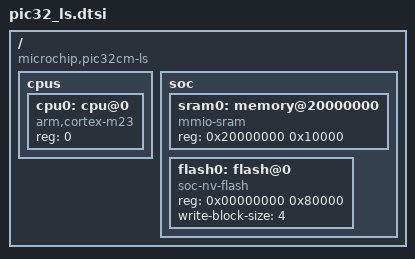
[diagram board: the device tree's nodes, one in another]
/*
 * Copyright (c) 2026
 *
 * SPDX-License-Identifier: Apache-2.0
 */

/* Common definitions for PIC32CM LS devices */

#include <arm/armv8-m.dtsi>

/ {
	compatible = "microchip,pic32cm-ls";

	cpus {
		#address-cells = <1>;
		#size-cells = <0>;

		cpu0: cpu@0 {
			device_type = "cpu";
			compatible = "arm,cortex-m23";
			reg = <0>;
		};
	};

	soc {
		#address-cells = <1>;
		#size-cells = <1>;

		sram0: memory@20000000 {
			compatible = "mmio-sram";
			reg = <0x20000000 0x10000>;
		};

		flash0: flash@0 {
			compatible = "soc-nv-flash";
			reg = <0x00000000 0x80000>;
			write-block-size = <4>;
		};
	};
};
